# AUX_AIODIO register map
Vendor: Texas Instruments
Peripheral module from a debugger description file (folder CC26x0R2F).
Registers are 32-bit, access per field, reset 0x0 unless marked. A register's access mark holds for its fields unless they carry their own. Offsets are as the file gives them; lines under a group give offsets from that group; [hi:lo] are bit positions; {n}, {i} and the like mark numbered series; 'fields as' and 'values as' point back to an identical list; <NAME> marks a mode.

## AUX_AIODIO — AUX Analog/Digital Input Output Controller
0x00 GPIODOUT — General Purpose Input Output Data Out The output data register is used to set data on AUXIO that are controlled by instance i of AUX_AIODIO. Hence, in formulas below i = 0 for AUX_AIODIO0 and i = 1 for AUX_AIODIO1
  [7:0] IO7_0 rw — Write 1 to bit index n in this bit vector to set AUXIO[8i+n]. Write 0 to bit index n in this bit vector to clear AUXIO[8i+n].
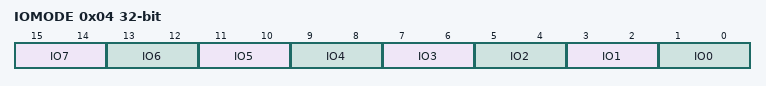
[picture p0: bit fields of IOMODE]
0x04 IOMODE — Input Output Mode This register controls pull-up, pull-down, and output mode for AUXIO that are controlled by instance i of AUX_AIODIO. Hence, in formulas below i = 0 for AUX_AIODIO0 and i = 1 for AUX_AIODIO1
  [15:14] IO7 rw — Select mode for AUXIO[8i+7].
    3=OPEN_SOURCE (Open-Source Mode: When GPIODOUT bit 7 is 0: AUXIO[8i+7] is tri-stated or pulled. This depends on IOC:IOCFGn.PULL_CTL. When GPIODOUT bit 7 is 1: AUXIO[8i+7] is driven high.); 2=OPEN_DRAIN (Open-Drain Mode: When GPIODOUT bit 7 is 0: AUXIO[8i+7] is driven low. When GPIODOUT bit 7 is 1: AUXIO[8i+7] is tri-stated or pulled. This depends on IOC:IOCFGn.PULL_CTL.); 1=IN (Input Mode: When GPIODIE bit 7 is 0: AUXIO[8i+7] is enabled for analog signal transfer. When GPIODIE bit 7 is 1: AUXIO[8i+7] is enabled for digital input.); 0=OUT (Output Mode: GPIODOUT bit 7 drives AUXIO[8i+7].)
  [13:12] IO6 rw — Select mode for AUXIO[8i+6].
    3=OPEN_SOURCE (Open-Source Mode: When GPIODOUT bit 6 is 0: AUXIO[8i+6] is tri-stated or pulled. This depends on IOC:IOCFGn.PULL_CTL. When GPIODOUT bit 6 is 1: AUXIO[8i+6] is driven high.); 2=OPEN_DRAIN (Open-Drain Mode: When GPIODOUT bit 6 is 0: AUXIO[8i+6] is driven low. When GPIODOUT bit 6 is 1: AUXIO[8i+6] is tri-stated or pulled. This depends on IOC:IOCFGn.PULL_CTL.); 1=IN (Input Mode: When GPIODIE bit 6 is 0: AUXIO[8i+6] is enabled for analog signal transfer. When GPIODIE bit 6 is 1: AUXIO[8i+6] is enabled for digital input.); 0=OUT (Output Mode: GPIODOUT bit 6 drives AUXIO[8i+6].)
  [11:10] IO5 rw — Select mode for AUXIO[8i+5].
    3=OPEN_SOURCE (Open-Source Mode: When GPIODOUT bit 5 is 0: AUXIO[8i+5] is tri-stated or pulled. This depends on IOC:IOCFGn.PULL_CTL. When GPIODOUT bit 5 is 1: AUXIO[8i+5] is driven high.); 2=OPEN_DRAIN (Open-Drain Mode: When GPIODOUT bit 5 is 0: AUXIO[8i+5] is driven low. When GPIODOUT bit 5 is 1: AUXIO[8i+5] is tri-stated or pulled. This depends on IOC:IOCFGn.PULL_CTL.); 1=IN (Input Mode: When GPIODIE bit 5 is 0: AUXIO[8i+5] is enabled for analog signal transfer. When GPIODIE bit 5 is 1: AUXIO[8i+5] is enabled for digital input.); 0=OUT (Output Mode: GPIODOUT bit 5 drives AUXIO[8i+5].)
  [9:8] IO4 rw — Select mode for AUXIO[8i+4].
    3=OPEN_SOURCE (Open-Source Mode: When GPIODOUT bit 4 is 0: AUXIO[8i+4] is tri-stated or pulled. This depends on IOC:IOCFGn.PULL_CTL. When GPIODOUT bit 4 is 1: AUXIO[8i+4] is driven high.); 2=OPEN_DRAIN (Open-Drain Mode: When GPIODOUT bit 4 is 0: AUXIO[8i+4] is driven low. When GPIODOUT bit 4 is 1: AUXIO[8i+4] is tri-stated or pulled. This depends on IOC:IOCFGn.PULL_CTL.); 1=IN (Input Mode: When GPIODIE bit 4 is 0: AUXIO[8i+4] is enabled for analog signal transfer. When GPIODIE bit 4 is 1: AUXIO[8i+4] is enabled for digital input.); 0=OUT (Output Mode: GPIODOUT bit 4 drives AUXIO[8i+4].)
  [7:6] IO3 rw — Select mode for AUXIO[8i+3].
    3=OPEN_SOURCE (Open-Source Mode: When GPIODOUT bit 3 is 0: AUXIO[8i+3] is tri-stated or pulled. This depends on IOC:IOCFGn.PULL_CTL. When GPIODOUT bit 3 is 1: AUXIO[8i+3] is driven high.); 2=OPEN_DRAIN (Open-Drain Mode: When GPIODOUT bit 3 is 0: AUXIO[8i+3] is driven low. When GPIODOUT bit 3 is 1: AUXIO[8i+3] is tri-stated or pulled. This depends on IOC:IOCFGn.PULL_CTL.); 1=IN (Input Mode: When GPIODIE bit 3 is 0: AUXIO[8i+3] is enabled for analog signal transfer. When GPIODIE bit 3 is 1: AUXIO[8i+3] is enabled for digital input.); 0=OUT (Output Mode: GPIODOUT bit 3 drives AUXIO[8i+3].)
  [5:4] IO2 rw — Select mode for AUXIO[8i+2].
    3=OPEN_SOURCE (Open-Source Mode: When GPIODOUT bit 2 is 0: AUXIO[8i+2] is tri-stated or pulled. This depends on IOC:IOCFGn.PULL_CTL. When GPIODOUT bit 2 is 1: AUXIO[8i+2] is driven high.); 2=OPEN_DRAIN (Open-Drain Mode: When GPIODOUT bit 2 is 0: AUXIO[8i+2] is driven low. When GPIODOUT bit 2 is 1: AUXIO[8i+2] is tri-stated or pulled. This depends on IOC:IOCFGn.PULL_CTL.); 1=IN (Input Mode: When GPIODIE bit 2 is 0: AUXIO[8i+2] is enabled for analog signal transfer. When GPIODIE bit 2 is 1: AUXIO[8i+2] is enabled for digital input.); 0=OUT (Output Mode: GPIODOUT bit 2 drives AUXIO[8i+2].)
  [3:2] IO1 rw — Select mode for AUXIO[8i+1].
    3=OPEN_SOURCE (Open-Source Mode: When GPIODOUT bit 1 is 0: AUXIO[8i+1] is tri-stated or pulled. This depends on IOC:IOCFGn.PULL_CTL. When GPIODOUT bit 1 is 1: AUXIO[8i+1] is driven high.); 2=OPEN_DRAIN (Open-Drain Mode: When GPIODOUT bit 1 is 0: AUXIO[8i+1] is driven low. When GPIODOUT bit 1 is 1: AUXIO[8i+1] is tri-stated or pulled. This depends on IOC:IOCFGn.PULL_CTL.); 1=IN (Input Mode: When GPIODIE bit 1 is 0: AUXIO[8i+1] is enabled for analog signal transfer. When GPIODIE bit 1 is 1: AUXIO[8i+1] is enabled for digital input.); 0=OUT (Output Mode: GPIODOUT bit 1 drives AUXIO[8i+1].)
  [1:0] IO0 rw — Select mode for AUXIO[8i+0].
    3=OPEN_SOURCE (Open-Source Mode: When GPIODOUT bit 0 is 0: AUXIO[8i+0] is tri-stated or pulled. This depends on IOC:IOCFGn.PULL_CTL. When GPIODOUT bit 0 is 1: AUXIO[8i+0] is driven high.); 2=OPEN_DRAIN (Open-Drain Mode: When GPIODOUT bit 0 is 0: AUXIO[8i+0] is driven low. When GPIODOUT bit 0 is 1: AUXIO[8i+0] is tri-stated or pulled. This depends on IOC:IOCFGn.PULL_CTL.); 1=IN (Input Mode: When GPIODIE bit 0 is 0: AUXIO[8i+0] is enabled for analog signal transfer. When GPIODIE bit 0 is 1: AUXIO[8i+0] is enabled for digital input.); 0=OUT (Output Mode: GPIODOUT bit 0 drives AUXIO[8i+0].)
0x08 GPIODIN ro — General Purpose Input Output Data In This register provides synchronized input data for AUXIO that are controlled by instance i of AUX_AIODIO. Hence, in formulas below i = 0 for AUX_AIODIO0 and I = 1 for AUX_AIODIO1.
  [7:0] IO7_0 — Bit n in this bit vector contains the value for AUXIO[8i+n] when GPIODIE bit n is set. Otherwise, bit n value is old.
0x0C GPIODOUTSET — General Purpose Input Output Data Out Set Set bits in GPIODOUT in instance i of AUX_AIODIO. Hence, in formulas below i = 0 for AUX_AIODIO0 and i = 1 for AUX_AIODIO1.
  [7:0] IO7_0 rw — Write 1 to bit index n in this bit vector to set GPIODOUT bit n. Read value is 0.
0x10 GPIODOUTCLR — General Purpose Input Output Data Out Clear Clear bits in GPIODOUT instance i of AUX_AIODIO. Hence, in formulas below i = 0 for AUX_AIODIO0 and i = 1 for AUX_AIODIO1.
  [7:0] IO7_0 rw — Write 1 to bit index n in this bit vector to clear GPIODOUT bit n. Read value is 0.
0x14 GPIODOUTTGL — General Purpose Input Output Data Out Toggle Toggle bits in GPIODOUT in instance i of AUX_AIODIO. Hence, in formulas below i = 0 for AUX_AIODIO0 and i = 1 for AUX_AIODIO1.
  [7:0] IO7_0 rw — Write 1 to bit index n in this bit vector to toggle GPIODOUT bit n. Read value is 0.
0x18 GPIODIE — General Purpose Input Output Digital Input Enable This register controls input buffers for AUXIO that are controlled by instance i of AUX_AIODIO. Hence, in formulas below i = 0 for AUX_AIODIO0 and I = 1 for AUX_AIODIO1.
  [7:0] IO7_0 rw — Write 1 to bit index n in this bit vector to enable digital input buffer for AUXIO[8i+n]. Write 0 to bit index n in this bit vector to disable digital input buffer for AUXIO[8i+n]. You must enable the digital input buffer for AUXIO[8i+n] to read the pin value in GPIODIN. You must disable the digital input buffer for analog input or pins that float to avoid current leakage.
